# MSS_CTRL_MSS_CTRL_50D00000h register map
Vendor: Texas Instruments
Registers are 32-bit, read-write, reset values left out (the file's numbers can be read two ways) unless marked. A register's access mark holds for its fields unless they carry their own. Offsets are as the file gives them; [hi:lo] are bit positions; {n}, {i} and the like mark numbered series.

## MSS_CTRL (part 4 of 6)
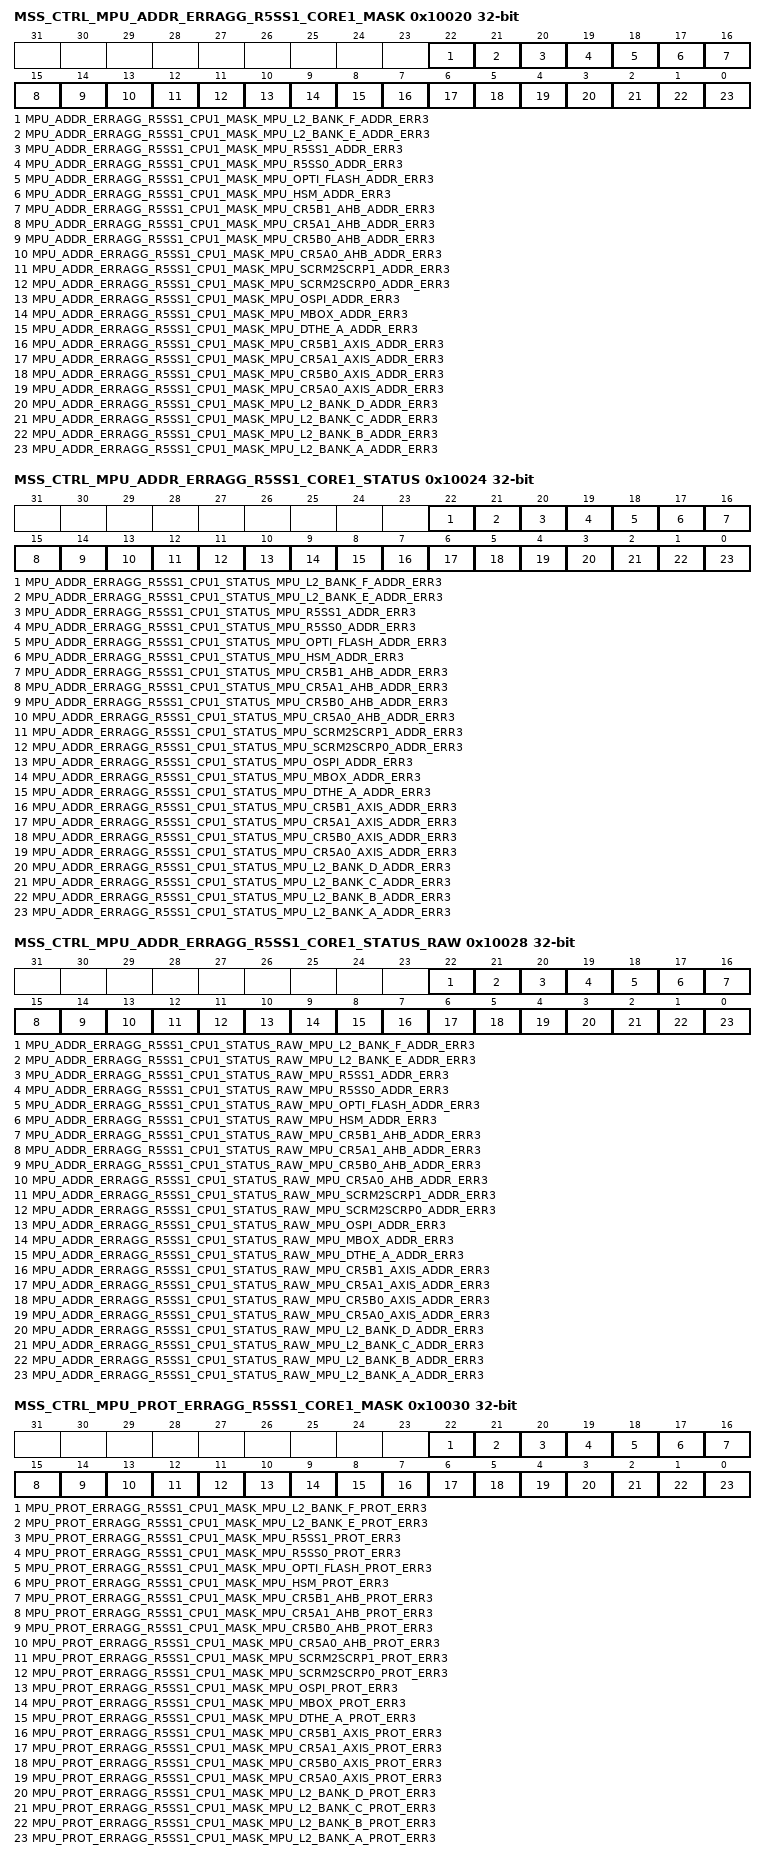
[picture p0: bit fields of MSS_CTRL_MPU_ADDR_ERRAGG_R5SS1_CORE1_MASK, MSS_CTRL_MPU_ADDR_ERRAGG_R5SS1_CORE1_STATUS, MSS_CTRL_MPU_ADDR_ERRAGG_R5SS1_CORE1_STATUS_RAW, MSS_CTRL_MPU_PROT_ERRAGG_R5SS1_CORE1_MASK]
0x10020 MSS_CTRL_MPU_ADDR_ERRAGG_R5SS1_CORE1_MASK
  [22] MPU_ADDR_ERRAGG_R5SS1_CPU1_MASK_MPU_L2_BANK_F_ADDR_ERR3 — Mask Error from MPU_ADDR_INTR to aggregated Error MPU_ADDR_INTR_ERRAGG1'b1 : Error is Masked1'b0 : Error is Unmasked
  [21] MPU_ADDR_ERRAGG_R5SS1_CPU1_MASK_MPU_L2_BANK_E_ADDR_ERR3 — Mask Error from MPU_ADDR_INTR to aggregated Error MPU_ADDR_INTR_ERRAGG1'b1 : Error is Masked1'b0 : Error is Unmasked
  [20] MPU_ADDR_ERRAGG_R5SS1_CPU1_MASK_MPU_R5SS1_ADDR_ERR3 — Mask Error from MPU_ADDR_INTR to aggregated Error MPU_ADDR_INTR_ERRAGG1'b1 : Error is Masked1'b0 : Error is Unmasked
  [19] MPU_ADDR_ERRAGG_R5SS1_CPU1_MASK_MPU_R5SS0_ADDR_ERR3 — Mask Error from MPU_ADDR_INTR to aggregated Error MPU_ADDR_INTR_ERRAGG1'b1 : Error is Masked1'b0 : Error is Unmasked
  [18] MPU_ADDR_ERRAGG_R5SS1_CPU1_MASK_MPU_OPTI_FLASH_ADDR_ERR3 — Mask Error from MPU_ADDR_INTR to aggregated Error MPU_ADDR_INTR_ERRAGG1'b1 : Error is Masked1'b0 : Error is Unmasked
  [17] MPU_ADDR_ERRAGG_R5SS1_CPU1_MASK_MPU_HSM_ADDR_ERR3 — Mask Error from MPU_ADDR_INTR to aggregated Error MPU_ADDR_INTR_ERRAGG1'b1 : Error is Masked1'b0 : Error is Unmasked
  [16] MPU_ADDR_ERRAGG_R5SS1_CPU1_MASK_MPU_CR5B1_AHB_ADDR_ERR3 — Mask Error from MPU_ADDR_INTR to aggregated Error MPU_ADDR_INTR_ERRAGG1'b1 : Error is Masked1'b0 : Error is Unmasked
  [15] MPU_ADDR_ERRAGG_R5SS1_CPU1_MASK_MPU_CR5A1_AHB_ADDR_ERR3 — Mask Error from MPU_ADDR_INTR to aggregated Error MPU_ADDR_INTR_ERRAGG1'b1 : Error is Masked1'b0 : Error is Unmasked
  [14] MPU_ADDR_ERRAGG_R5SS1_CPU1_MASK_MPU_CR5B0_AHB_ADDR_ERR3 — Mask Error from MPU_ADDR_INTR to aggregated Error MPU_ADDR_INTR_ERRAGG1'b1 : Error is Masked1'b0 : Error is Unmasked
  [13] MPU_ADDR_ERRAGG_R5SS1_CPU1_MASK_MPU_CR5A0_AHB_ADDR_ERR3 — Mask Error from MPU_ADDR_INTR to aggregated Error MPU_ADDR_INTR_ERRAGG1'b1 : Error is Masked1'b0 : Error is Unmasked
  [12] MPU_ADDR_ERRAGG_R5SS1_CPU1_MASK_MPU_SCRM2SCRP1_ADDR_ERR3 — Mask Error from MPU_ADDR_INTR to aggregated Error MPU_ADDR_INTR_ERRAGG1'b1 : Error is Masked1'b0 : Error is Unmasked
  [11] MPU_ADDR_ERRAGG_R5SS1_CPU1_MASK_MPU_SCRM2SCRP0_ADDR_ERR3 — Mask Error from MPU_ADDR_INTR to aggregated Error MPU_ADDR_INTR_ERRAGG1'b1 : Error is Masked1'b0 : Error is Unmasked
  [10] MPU_ADDR_ERRAGG_R5SS1_CPU1_MASK_MPU_OSPI_ADDR_ERR3 — Mask Error from MPU_ADDR_INTR to aggregated Error MPU_ADDR_INTR_ERRAGG1'b1 : Error is Masked1'b0 : Error is Unmasked
  [9] MPU_ADDR_ERRAGG_R5SS1_CPU1_MASK_MPU_MBOX_ADDR_ERR3 — Mask Error from MPU_ADDR_INTR to aggregated Error MPU_ADDR_INTR_ERRAGG1'b1 : Error is Masked1'b0 : Error is Unmasked
  [8] MPU_ADDR_ERRAGG_R5SS1_CPU1_MASK_MPU_DTHE_A_ADDR_ERR3 — Mask Error from MPU_ADDR_INTR to aggregated Error MPU_ADDR_INTR_ERRAGG1'b1 : Error is Masked1'b0 : Error is Unmasked
  [7] MPU_ADDR_ERRAGG_R5SS1_CPU1_MASK_MPU_CR5B1_AXIS_ADDR_ERR3 — Mask Error from MPU_ADDR_INTR to aggregated Error MPU_ADDR_INTR_ERRAGG1'b1 : Error is Masked1'b0 : Error is Unmasked
  [6] MPU_ADDR_ERRAGG_R5SS1_CPU1_MASK_MPU_CR5A1_AXIS_ADDR_ERR3 — Mask Error from MPU_ADDR_INTR to aggregated Error MPU_ADDR_INTR_ERRAGG1'b1 : Error is Masked1'b0 : Error is Unmasked
  [5] MPU_ADDR_ERRAGG_R5SS1_CPU1_MASK_MPU_CR5B0_AXIS_ADDR_ERR3 — Mask Error from MPU_ADDR_INTR to aggregated Error MPU_ADDR_INTR_ERRAGG1'b1 : Error is Masked1'b0 : Error is Unmasked
  [4] MPU_ADDR_ERRAGG_R5SS1_CPU1_MASK_MPU_CR5A0_AXIS_ADDR_ERR3 — Mask Error from MPU_ADDR_INTR to aggregated Error MPU_ADDR_INTR_ERRAGG1'b1 : Error is Masked1'b0 : Error is Unmasked
  [3] MPU_ADDR_ERRAGG_R5SS1_CPU1_MASK_MPU_L2_BANK_D_ADDR_ERR3 — Mask Error from MPU_ADDR_INTR to aggregated Error MPU_ADDR_INTR_ERRAGG1'b1 : Error is Masked1'b0 : Error is Unmasked
  [2] MPU_ADDR_ERRAGG_R5SS1_CPU1_MASK_MPU_L2_BANK_C_ADDR_ERR3 — Mask Error from MPU_ADDR_INTR to aggregated Error MPU_ADDR_INTR_ERRAGG1'b1 : Error is Masked1'b0 : Error is Unmasked
  [1] MPU_ADDR_ERRAGG_R5SS1_CPU1_MASK_MPU_L2_BANK_B_ADDR_ERR3 — Mask Error from MPU_ADDR_INTR to aggregated Error MPU_ADDR_INTR_ERRAGG1'b1 : Error is Masked1'b0 : Error is Unmasked
  [0] MPU_ADDR_ERRAGG_R5SS1_CPU1_MASK_MPU_L2_BANK_A_ADDR_ERR3 — Mask Error from MPU_ADDR_INTR to aggregated Error MPU_ADDR_INTR_ERRAGG1'b1 : Error is Masked1'b0 : Error is Unmasked
0x10024 MSS_CTRL_MPU_ADDR_ERRAGG_R5SS1_CORE1_STATUS
  [22] MPU_ADDR_ERRAGG_R5SS1_CPU1_STATUS_MPU_L2_BANK_F_ADDR_ERR3 — Status of Error from MPU_ADDR_INTR. Set only if Interupt is unmasked in MPU_ADDR_INTR_ERRAGG_MASKWrie 0x1 to clear this Error.
  [21] MPU_ADDR_ERRAGG_R5SS1_CPU1_STATUS_MPU_L2_BANK_E_ADDR_ERR3 — Status of Error from MPU_ADDR_INTR. Set only if Interupt is unmasked in MPU_ADDR_INTR_ERRAGG_MASKWrie 0x1 to clear this Error.
  [20] MPU_ADDR_ERRAGG_R5SS1_CPU1_STATUS_MPU_R5SS1_ADDR_ERR3 — Status of Error from MPU_ADDR_INTR. Set only if Interupt is unmasked in MPU_ADDR_INTR_ERRAGG_MASKWrie 0x1 to clear this Error.
  [19] MPU_ADDR_ERRAGG_R5SS1_CPU1_STATUS_MPU_R5SS0_ADDR_ERR3 — Status of Error from MPU_ADDR_INTR. Set only if Interupt is unmasked in MPU_ADDR_INTR_ERRAGG_MASKWrie 0x1 to clear this Error.
  [18] MPU_ADDR_ERRAGG_R5SS1_CPU1_STATUS_MPU_OPTI_FLASH_ADDR_ERR3 — Status of Error from MPU_ADDR_INTR. Set only if Interupt is unmasked in MPU_ADDR_INTR_ERRAGG_MASKWrie 0x1 to clear this Error.
  [17] MPU_ADDR_ERRAGG_R5SS1_CPU1_STATUS_MPU_HSM_ADDR_ERR3 — Status of Error from MPU_ADDR_INTR. Set only if Interupt is unmasked in MPU_ADDR_INTR_ERRAGG_MASKWrie 0x1 to clear this Error.
  [16] MPU_ADDR_ERRAGG_R5SS1_CPU1_STATUS_MPU_CR5B1_AHB_ADDR_ERR3 — Status of Error from MPU_ADDR_INTR. Set only if Interupt is unmasked in MPU_ADDR_INTR_ERRAGG_MASKWrie 0x1 to clear this Error.
  [15] MPU_ADDR_ERRAGG_R5SS1_CPU1_STATUS_MPU_CR5A1_AHB_ADDR_ERR3 — Status of Error from MPU_ADDR_INTR. Set only if Interupt is unmasked in MPU_ADDR_INTR_ERRAGG_MASKWrie 0x1 to clear this Error.
  [14] MPU_ADDR_ERRAGG_R5SS1_CPU1_STATUS_MPU_CR5B0_AHB_ADDR_ERR3 — Status of Error from MPU_ADDR_INTR. Set only if Interupt is unmasked in MPU_ADDR_INTR_ERRAGG_MASKWrie 0x1 to clear this Error.
  [13] MPU_ADDR_ERRAGG_R5SS1_CPU1_STATUS_MPU_CR5A0_AHB_ADDR_ERR3 — Status of Error from MPU_ADDR_INTR. Set only if Interupt is unmasked in MPU_ADDR_INTR_ERRAGG_MASKWrie 0x1 to clear this Error.
  [12] MPU_ADDR_ERRAGG_R5SS1_CPU1_STATUS_MPU_SCRM2SCRP1_ADDR_ERR3 — Status of Error from MPU_ADDR_INTR. Set only if Interupt is unmasked in MPU_ADDR_INTR_ERRAGG_MASKWrie 0x1 to clear this Error.
  [11] MPU_ADDR_ERRAGG_R5SS1_CPU1_STATUS_MPU_SCRM2SCRP0_ADDR_ERR3 — Status of Error from MPU_ADDR_INTR. Set only if Interupt is unmasked in MPU_ADDR_INTR_ERRAGG_MASKWrie 0x1 to clear this Error.
  [10] MPU_ADDR_ERRAGG_R5SS1_CPU1_STATUS_MPU_OSPI_ADDR_ERR3 — Status of Error from MPU_ADDR_INTR. Set only if Interupt is unmasked in MPU_ADDR_INTR_ERRAGG_MASKWrie 0x1 to clear this Error.
  [9] MPU_ADDR_ERRAGG_R5SS1_CPU1_STATUS_MPU_MBOX_ADDR_ERR3 — Status of Error from MPU_ADDR_INTR. Set only if Interupt is unmasked in MPU_ADDR_INTR_ERRAGG_MASKWrie 0x1 to clear this Error.
  [8] MPU_ADDR_ERRAGG_R5SS1_CPU1_STATUS_MPU_DTHE_A_ADDR_ERR3 — Status of Error from MPU_ADDR_INTR. Set only if Interupt is unmasked in MPU_ADDR_INTR_ERRAGG_MASKWrie 0x1 to clear this Error.
  [7] MPU_ADDR_ERRAGG_R5SS1_CPU1_STATUS_MPU_CR5B1_AXIS_ADDR_ERR3 — Status of Error from MPU_ADDR_INTR. Set only if Interupt is unmasked in MPU_ADDR_INTR_ERRAGG_MASKWrie 0x1 to clear this Error.
  [6] MPU_ADDR_ERRAGG_R5SS1_CPU1_STATUS_MPU_CR5A1_AXIS_ADDR_ERR3 — Status of Error from MPU_ADDR_INTR. Set only if Interupt is unmasked in MPU_ADDR_INTR_ERRAGG_MASKWrie 0x1 to clear this Error.
  [5] MPU_ADDR_ERRAGG_R5SS1_CPU1_STATUS_MPU_CR5B0_AXIS_ADDR_ERR3 — Status of Error from MPU_ADDR_INTR. Set only if Interupt is unmasked in MPU_ADDR_INTR_ERRAGG_MASKWrie 0x1 to clear this Error.
  [4] MPU_ADDR_ERRAGG_R5SS1_CPU1_STATUS_MPU_CR5A0_AXIS_ADDR_ERR3 — Status of Error from MPU_ADDR_INTR. Set only if Interupt is unmasked in MPU_ADDR_INTR_ERRAGG_MASKWrie 0x1 to clear this Error.
  [3] MPU_ADDR_ERRAGG_R5SS1_CPU1_STATUS_MPU_L2_BANK_D_ADDR_ERR3 — Status of Error from MPU_ADDR_INTR. Set only if Interupt is unmasked in MPU_ADDR_INTR_ERRAGG_MASKWrie 0x1 to clear this Error.
  [2] MPU_ADDR_ERRAGG_R5SS1_CPU1_STATUS_MPU_L2_BANK_C_ADDR_ERR3 — Status of Error from MPU_ADDR_INTR. Set only if Interupt is unmasked in MPU_ADDR_INTR_ERRAGG_MASKWrie 0x1 to clear this Error.
  [1] MPU_ADDR_ERRAGG_R5SS1_CPU1_STATUS_MPU_L2_BANK_B_ADDR_ERR3 — Status of Error from MPU_ADDR_INTR. Set only if Interupt is unmasked in MPU_ADDR_INTR_ERRAGG_MASKWrie 0x1 to clear this Error.
  [0] MPU_ADDR_ERRAGG_R5SS1_CPU1_STATUS_MPU_L2_BANK_A_ADDR_ERR3 — Status of Error from MPU_ADDR_INTR. Set only if Interupt is unmasked in MPU_ADDR_INTR_ERRAGG_MASKWrie 0x1 to clear this Error.
0x10028 MSS_CTRL_MPU_ADDR_ERRAGG_R5SS1_CORE1_STATUS_RAW
  [22] MPU_ADDR_ERRAGG_R5SS1_CPU1_STATUS_RAW_MPU_L2_BANK_F_ADDR_ERR3 — Raw Status of Error from MPU_ADDR_INTR. Set irrespective if the Interupt is masked or unmasked in MPU_ADDR_INTR_ERRAGG_MASK
  [21] MPU_ADDR_ERRAGG_R5SS1_CPU1_STATUS_RAW_MPU_L2_BANK_E_ADDR_ERR3 — Raw Status of Error from MPU_ADDR_INTR. Set irrespective if the Interupt is masked or unmasked in MPU_ADDR_INTR_ERRAGG_MASK
  [20] MPU_ADDR_ERRAGG_R5SS1_CPU1_STATUS_RAW_MPU_R5SS1_ADDR_ERR3 — Raw Status of Error from MPU_ADDR_INTR. Set irrespective if the Interupt is masked or unmasked in MPU_ADDR_INTR_ERRAGG_MASK
  [19] MPU_ADDR_ERRAGG_R5SS1_CPU1_STATUS_RAW_MPU_R5SS0_ADDR_ERR3 — Raw Status of Error from MPU_ADDR_INTR. Set irrespective if the Interupt is masked or unmasked in MPU_ADDR_INTR_ERRAGG_MASK
  [18] MPU_ADDR_ERRAGG_R5SS1_CPU1_STATUS_RAW_MPU_OPTI_FLASH_ADDR_ERR3 — Raw Status of Error from MPU_ADDR_INTR. Set irrespective if the Interupt is masked or unmasked in MPU_ADDR_INTR_ERRAGG_MASK
  [17] MPU_ADDR_ERRAGG_R5SS1_CPU1_STATUS_RAW_MPU_HSM_ADDR_ERR3 — Raw Status of Error from MPU_ADDR_INTR. Set irrespective if the Interupt is masked or unmasked in MPU_ADDR_INTR_ERRAGG_MASK
  [16] MPU_ADDR_ERRAGG_R5SS1_CPU1_STATUS_RAW_MPU_CR5B1_AHB_ADDR_ERR3 — Raw Status of Error from MPU_ADDR_INTR. Set irrespective if the Interupt is masked or unmasked in MPU_ADDR_INTR_ERRAGG_MASK
  [15] MPU_ADDR_ERRAGG_R5SS1_CPU1_STATUS_RAW_MPU_CR5A1_AHB_ADDR_ERR3 — Raw Status of Error from MPU_ADDR_INTR. Set irrespective if the Interupt is masked or unmasked in MPU_ADDR_INTR_ERRAGG_MASK
  [14] MPU_ADDR_ERRAGG_R5SS1_CPU1_STATUS_RAW_MPU_CR5B0_AHB_ADDR_ERR3 — Raw Status of Error from MPU_ADDR_INTR. Set irrespective if the Interupt is masked or unmasked in MPU_ADDR_INTR_ERRAGG_MASK
  [13] MPU_ADDR_ERRAGG_R5SS1_CPU1_STATUS_RAW_MPU_CR5A0_AHB_ADDR_ERR3 — Raw Status of Error from MPU_ADDR_INTR. Set irrespective if the Interupt is masked or unmasked in MPU_ADDR_INTR_ERRAGG_MASK
  [12] MPU_ADDR_ERRAGG_R5SS1_CPU1_STATUS_RAW_MPU_SCRM2SCRP1_ADDR_ERR3 — Raw Status of Error from MPU_ADDR_INTR. Set irrespective if the Interupt is masked or unmasked in MPU_ADDR_INTR_ERRAGG_MASK
  [11] MPU_ADDR_ERRAGG_R5SS1_CPU1_STATUS_RAW_MPU_SCRM2SCRP0_ADDR_ERR3 — Raw Status of Error from MPU_ADDR_INTR. Set irrespective if the Interupt is masked or unmasked in MPU_ADDR_INTR_ERRAGG_MASK
  [10] MPU_ADDR_ERRAGG_R5SS1_CPU1_STATUS_RAW_MPU_OSPI_ADDR_ERR3 — Raw Status of Error from MPU_ADDR_INTR. Set irrespective if the Interupt is masked or unmasked in MPU_ADDR_INTR_ERRAGG_MASK
  [9] MPU_ADDR_ERRAGG_R5SS1_CPU1_STATUS_RAW_MPU_MBOX_ADDR_ERR3 — Raw Status of Error from MPU_ADDR_INTR. Set irrespective if the Interupt is masked or unmasked in MPU_ADDR_INTR_ERRAGG_MASK
  [8] MPU_ADDR_ERRAGG_R5SS1_CPU1_STATUS_RAW_MPU_DTHE_A_ADDR_ERR3 — Raw Status of Error from MPU_ADDR_INTR. Set irrespective if the Interupt is masked or unmasked in MPU_ADDR_INTR_ERRAGG_MASK
  [7] MPU_ADDR_ERRAGG_R5SS1_CPU1_STATUS_RAW_MPU_CR5B1_AXIS_ADDR_ERR3 — Raw Status of Error from MPU_ADDR_INTR. Set irrespective if the Interupt is masked or unmasked in MPU_ADDR_INTR_ERRAGG_MASK
  [6] MPU_ADDR_ERRAGG_R5SS1_CPU1_STATUS_RAW_MPU_CR5A1_AXIS_ADDR_ERR3 — Raw Status of Error from MPU_ADDR_INTR. Set irrespective if the Interupt is masked or unmasked in MPU_ADDR_INTR_ERRAGG_MASK
  [5] MPU_ADDR_ERRAGG_R5SS1_CPU1_STATUS_RAW_MPU_CR5B0_AXIS_ADDR_ERR3 — Raw Status of Error from MPU_ADDR_INTR. Set irrespective if the Interupt is masked or unmasked in MPU_ADDR_INTR_ERRAGG_MASK
  [4] MPU_ADDR_ERRAGG_R5SS1_CPU1_STATUS_RAW_MPU_CR5A0_AXIS_ADDR_ERR3 — Raw Status of Error from MPU_ADDR_INTR. Set irrespective if the Interupt is masked or unmasked in MPU_ADDR_INTR_ERRAGG_MASK
  [3] MPU_ADDR_ERRAGG_R5SS1_CPU1_STATUS_RAW_MPU_L2_BANK_D_ADDR_ERR3 — Raw Status of Error from MPU_ADDR_INTR. Set irrespective if the Interupt is masked or unmasked in MPU_ADDR_INTR_ERRAGG_MASK
  [2] MPU_ADDR_ERRAGG_R5SS1_CPU1_STATUS_RAW_MPU_L2_BANK_C_ADDR_ERR3 — Raw Status of Error from MPU_ADDR_INTR. Set irrespective if the Interupt is masked or unmasked in MPU_ADDR_INTR_ERRAGG_MASK
  [1] MPU_ADDR_ERRAGG_R5SS1_CPU1_STATUS_RAW_MPU_L2_BANK_B_ADDR_ERR3 — Raw Status of Error from MPU_ADDR_INTR. Set irrespective if the Interupt is masked or unmasked in MPU_ADDR_INTR_ERRAGG_MASK
  [0] MPU_ADDR_ERRAGG_R5SS1_CPU1_STATUS_RAW_MPU_L2_BANK_A_ADDR_ERR3 — Raw Status of Error from MPU_ADDR_INTR. Set irrespective if the Interupt is masked or unmasked in MPU_ADDR_INTR_ERRAGG_MASK
0x10030 MSS_CTRL_MPU_PROT_ERRAGG_R5SS1_CORE1_MASK
  [22] MPU_PROT_ERRAGG_R5SS1_CPU1_MASK_MPU_L2_BANK_F_PROT_ERR3 — Mask Error from MPU_PROT_INTR to aggregated Error MPU_PROT_INTR_ERRAGG1'b1 : Error is Masked1'b0 : Error is Unmasked
  [21] MPU_PROT_ERRAGG_R5SS1_CPU1_MASK_MPU_L2_BANK_E_PROT_ERR3 — Mask Error from MPU_PROT_INTR to aggregated Error MPU_PROT_INTR_ERRAGG1'b1 : Error is Masked1'b0 : Error is Unmasked
  [20] MPU_PROT_ERRAGG_R5SS1_CPU1_MASK_MPU_R5SS1_PROT_ERR3 — Mask Error from MPU_PROT_INTR to aggregated Error MPU_PROT_INTR_ERRAGG1'b1 : Error is Masked1'b0 : Error is Unmasked
  [19] MPU_PROT_ERRAGG_R5SS1_CPU1_MASK_MPU_R5SS0_PROT_ERR3 — Mask Error from MPU_PROT_INTR to aggregated Error MPU_PROT_INTR_ERRAGG1'b1 : Error is Masked1'b0 : Error is Unmasked
  [18] MPU_PROT_ERRAGG_R5SS1_CPU1_MASK_MPU_OPTI_FLASH_PROT_ERR3 — Mask Error from MPU_PROT_INTR to aggregated Error MPU_PROT_INTR_ERRAGG1'b1 : Error is Masked1'b0 : Error is Unmasked
  [17] MPU_PROT_ERRAGG_R5SS1_CPU1_MASK_MPU_HSM_PROT_ERR3 — Mask Error from MPU_PROT_INTR to aggregated Error MPU_PROT_INTR_ERRAGG1'b1 : Error is Masked1'b0 : Error is Unmasked
  [16] MPU_PROT_ERRAGG_R5SS1_CPU1_MASK_MPU_CR5B1_AHB_PROT_ERR3 — Mask Error from MPU_PROT_INTR to aggregated Error MPU_PROT_INTR_ERRAGG1'b1 : Error is Masked1'b0 : Error is Unmasked
  [15] MPU_PROT_ERRAGG_R5SS1_CPU1_MASK_MPU_CR5A1_AHB_PROT_ERR3 — Mask Error from MPU_PROT_INTR to aggregated Error MPU_PROT_INTR_ERRAGG1'b1 : Error is Masked1'b0 : Error is Unmasked
  [14] MPU_PROT_ERRAGG_R5SS1_CPU1_MASK_MPU_CR5B0_AHB_PROT_ERR3 — Mask Error from MPU_PROT_INTR to aggregated Error MPU_PROT_INTR_ERRAGG1'b1 : Error is Masked1'b0 : Error is Unmasked
  [13] MPU_PROT_ERRAGG_R5SS1_CPU1_MASK_MPU_CR5A0_AHB_PROT_ERR3 — Mask Error from MPU_PROT_INTR to aggregated Error MPU_PROT_INTR_ERRAGG1'b1 : Error is Masked1'b0 : Error is Unmasked
  [12] MPU_PROT_ERRAGG_R5SS1_CPU1_MASK_MPU_SCRM2SCRP1_PROT_ERR3 — Mask Error from MPU_PROT_INTR to aggregated Error MPU_PROT_INTR_ERRAGG1'b1 : Error is Masked1'b0 : Error is Unmasked
  [11] MPU_PROT_ERRAGG_R5SS1_CPU1_MASK_MPU_SCRM2SCRP0_PROT_ERR3 — Mask Error from MPU_PROT_INTR to aggregated Error MPU_PROT_INTR_ERRAGG1'b1 : Error is Masked1'b0 : Error is Unmasked
  [10] MPU_PROT_ERRAGG_R5SS1_CPU1_MASK_MPU_OSPI_PROT_ERR3 — Mask Error from MPU_PROT_INTR to aggregated Error MPU_PROT_INTR_ERRAGG1'b1 : Error is Masked1'b0 : Error is Unmasked
  [9] MPU_PROT_ERRAGG_R5SS1_CPU1_MASK_MPU_MBOX_PROT_ERR3 — Mask Error from MPU_PROT_INTR to aggregated Error MPU_PROT_INTR_ERRAGG1'b1 : Error is Masked1'b0 : Error is Unmasked
  [8] MPU_PROT_ERRAGG_R5SS1_CPU1_MASK_MPU_DTHE_A_PROT_ERR3 — Mask Error from MPU_PROT_INTR to aggregated Error MPU_PROT_INTR_ERRAGG1'b1 : Error is Masked1'b0 : Error is Unmasked
  [7] MPU_PROT_ERRAGG_R5SS1_CPU1_MASK_MPU_CR5B1_AXIS_PROT_ERR3 — Mask Error from MPU_PROT_INTR to aggregated Error MPU_PROT_INTR_ERRAGG1'b1 : Error is Masked1'b0 : Error is Unmasked
  [6] MPU_PROT_ERRAGG_R5SS1_CPU1_MASK_MPU_CR5A1_AXIS_PROT_ERR3 — Mask Error from MPU_PROT_INTR to aggregated Error MPU_PROT_INTR_ERRAGG1'b1 : Error is Masked1'b0 : Error is Unmasked
  [5] MPU_PROT_ERRAGG_R5SS1_CPU1_MASK_MPU_CR5B0_AXIS_PROT_ERR3 — Mask Error from MPU_PROT_INTR to aggregated Error MPU_PROT_INTR_ERRAGG1'b1 : Error is Masked1'b0 : Error is Unmasked
  [4] MPU_PROT_ERRAGG_R5SS1_CPU1_MASK_MPU_CR5A0_AXIS_PROT_ERR3 — Mask Error from MPU_PROT_INTR to aggregated Error MPU_PROT_INTR_ERRAGG1'b1 : Error is Masked1'b0 : Error is Unmasked
  [3] MPU_PROT_ERRAGG_R5SS1_CPU1_MASK_MPU_L2_BANK_D_PROT_ERR3 — Mask Error from MPU_PROT_INTR to aggregated Error MPU_PROT_INTR_ERRAGG1'b1 : Error is Masked1'b0 : Error is Unmasked
  [2] MPU_PROT_ERRAGG_R5SS1_CPU1_MASK_MPU_L2_BANK_C_PROT_ERR3 — Mask Error from MPU_PROT_INTR to aggregated Error MPU_PROT_INTR_ERRAGG1'b1 : Error is Masked1'b0 : Error is Unmasked
  [1] MPU_PROT_ERRAGG_R5SS1_CPU1_MASK_MPU_L2_BANK_B_PROT_ERR3 — Mask Error from MPU_PROT_INTR to aggregated Error MPU_PROT_INTR_ERRAGG1'b1 : Error is Masked1'b0 : Error is Unmasked
  [0] MPU_PROT_ERRAGG_R5SS1_CPU1_MASK_MPU_L2_BANK_A_PROT_ERR3 — Mask Error from MPU_PROT_INTR to aggregated Error MPU_PROT_INTR_ERRAGG1'b1 : Error is Masked1'b0 : Error is Unmasked
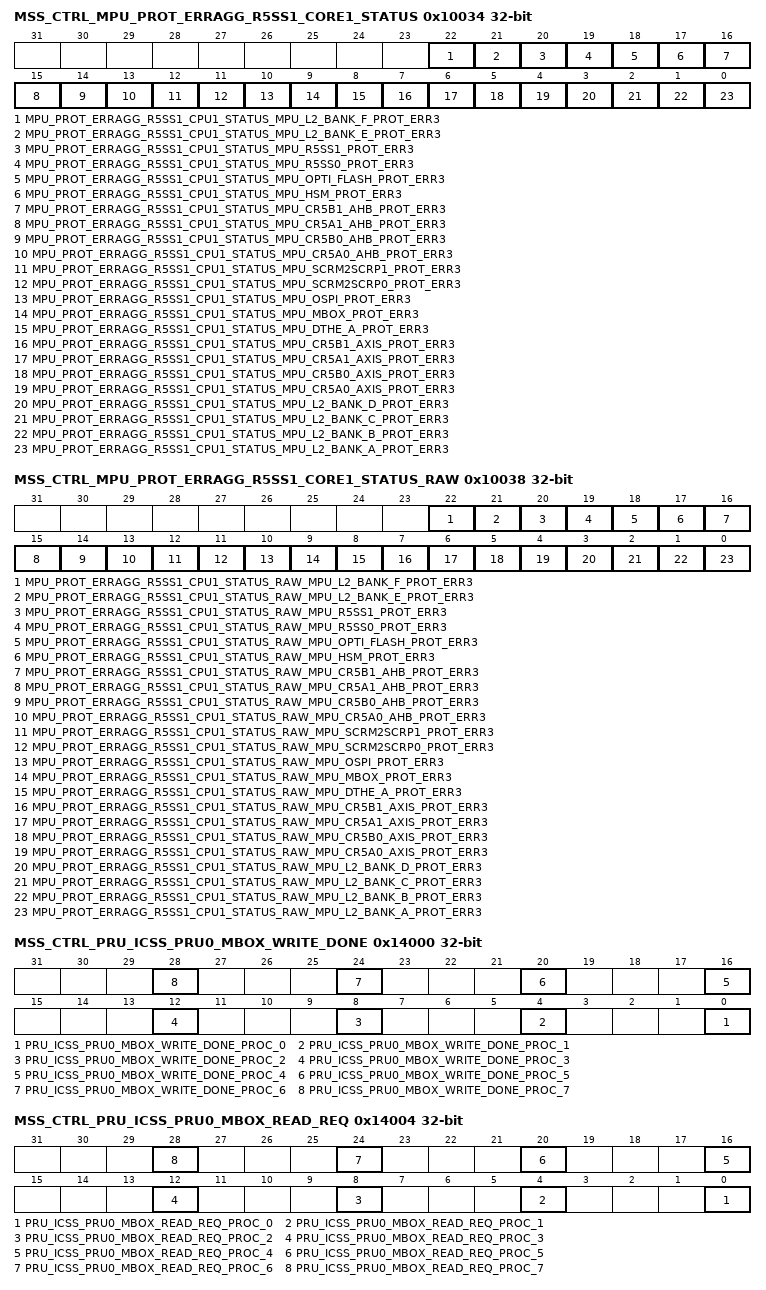
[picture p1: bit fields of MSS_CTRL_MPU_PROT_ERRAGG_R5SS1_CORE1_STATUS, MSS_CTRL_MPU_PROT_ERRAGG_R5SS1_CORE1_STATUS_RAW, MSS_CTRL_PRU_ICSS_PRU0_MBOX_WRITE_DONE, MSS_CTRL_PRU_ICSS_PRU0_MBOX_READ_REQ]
0x10034 MSS_CTRL_MPU_PROT_ERRAGG_R5SS1_CORE1_STATUS
  [22] MPU_PROT_ERRAGG_R5SS1_CPU1_STATUS_MPU_L2_BANK_F_PROT_ERR3 — Status of Error from MPU_PROT_INTR. Set only if Interupt is unmasked in MPU_PROT_INTR_ERRAGG_MASKWrie 0x1 to clear this Error.
  [21] MPU_PROT_ERRAGG_R5SS1_CPU1_STATUS_MPU_L2_BANK_E_PROT_ERR3 — Status of Error from MPU_PROT_INTR. Set only if Interupt is unmasked in MPU_PROT_INTR_ERRAGG_MASKWrie 0x1 to clear this Error.
  [20] MPU_PROT_ERRAGG_R5SS1_CPU1_STATUS_MPU_R5SS1_PROT_ERR3 — Status of Error from MPU_PROT_INTR. Set only if Interupt is unmasked in MPU_PROT_INTR_ERRAGG_MASKWrie 0x1 to clear this Error.
  [19] MPU_PROT_ERRAGG_R5SS1_CPU1_STATUS_MPU_R5SS0_PROT_ERR3 — Status of Error from MPU_PROT_INTR. Set only if Interupt is unmasked in MPU_PROT_INTR_ERRAGG_MASKWrie 0x1 to clear this Error.
  [18] MPU_PROT_ERRAGG_R5SS1_CPU1_STATUS_MPU_OPTI_FLASH_PROT_ERR3 — Status of Error from MPU_PROT_INTR. Set only if Interupt is unmasked in MPU_PROT_INTR_ERRAGG_MASKWrie 0x1 to clear this Error.
  [17] MPU_PROT_ERRAGG_R5SS1_CPU1_STATUS_MPU_HSM_PROT_ERR3 — Status of Error from MPU_PROT_INTR. Set only if Interupt is unmasked in MPU_PROT_INTR_ERRAGG_MASKWrie 0x1 to clear this Error.
  [16] MPU_PROT_ERRAGG_R5SS1_CPU1_STATUS_MPU_CR5B1_AHB_PROT_ERR3 — Status of Error from MPU_PROT_INTR. Set only if Interupt is unmasked in MPU_PROT_INTR_ERRAGG_MASKWrie 0x1 to clear this Error.
  [15] MPU_PROT_ERRAGG_R5SS1_CPU1_STATUS_MPU_CR5A1_AHB_PROT_ERR3 — Status of Error from MPU_PROT_INTR. Set only if Interupt is unmasked in MPU_PROT_INTR_ERRAGG_MASKWrie 0x1 to clear this Error.
  [14] MPU_PROT_ERRAGG_R5SS1_CPU1_STATUS_MPU_CR5B0_AHB_PROT_ERR3 — Status of Error from MPU_PROT_INTR. Set only if Interupt is unmasked in MPU_PROT_INTR_ERRAGG_MASKWrie 0x1 to clear this Error.
  [13] MPU_PROT_ERRAGG_R5SS1_CPU1_STATUS_MPU_CR5A0_AHB_PROT_ERR3 — Status of Error from MPU_PROT_INTR. Set only if Interupt is unmasked in MPU_PROT_INTR_ERRAGG_MASKWrie 0x1 to clear this Error.
  [12] MPU_PROT_ERRAGG_R5SS1_CPU1_STATUS_MPU_SCRM2SCRP1_PROT_ERR3 — Status of Error from MPU_PROT_INTR. Set only if Interupt is unmasked in MPU_PROT_INTR_ERRAGG_MASKWrie 0x1 to clear this Error.
  [11] MPU_PROT_ERRAGG_R5SS1_CPU1_STATUS_MPU_SCRM2SCRP0_PROT_ERR3 — Status of Error from MPU_PROT_INTR. Set only if Interupt is unmasked in MPU_PROT_INTR_ERRAGG_MASKWrie 0x1 to clear this Error.
  [10] MPU_PROT_ERRAGG_R5SS1_CPU1_STATUS_MPU_OSPI_PROT_ERR3 — Status of Error from MPU_PROT_INTR. Set only if Interupt is unmasked in MPU_PROT_INTR_ERRAGG_MASKWrie 0x1 to clear this Error.
  [9] MPU_PROT_ERRAGG_R5SS1_CPU1_STATUS_MPU_MBOX_PROT_ERR3 — Status of Error from MPU_PROT_INTR. Set only if Interupt is unmasked in MPU_PROT_INTR_ERRAGG_MASKWrie 0x1 to clear this Error.
  [8] MPU_PROT_ERRAGG_R5SS1_CPU1_STATUS_MPU_DTHE_A_PROT_ERR3 — Status of Error from MPU_PROT_INTR. Set only if Interupt is unmasked in MPU_PROT_INTR_ERRAGG_MASKWrie 0x1 to clear this Error.
  [7] MPU_PROT_ERRAGG_R5SS1_CPU1_STATUS_MPU_CR5B1_AXIS_PROT_ERR3 — Status of Error from MPU_PROT_INTR. Set only if Interupt is unmasked in MPU_PROT_INTR_ERRAGG_MASKWrie 0x1 to clear this Error.
  [6] MPU_PROT_ERRAGG_R5SS1_CPU1_STATUS_MPU_CR5A1_AXIS_PROT_ERR3 — Status of Error from MPU_PROT_INTR. Set only if Interupt is unmasked in MPU_PROT_INTR_ERRAGG_MASKWrie 0x1 to clear this Error.
  [5] MPU_PROT_ERRAGG_R5SS1_CPU1_STATUS_MPU_CR5B0_AXIS_PROT_ERR3 — Status of Error from MPU_PROT_INTR. Set only if Interupt is unmasked in MPU_PROT_INTR_ERRAGG_MASKWrie 0x1 to clear this Error.
  [4] MPU_PROT_ERRAGG_R5SS1_CPU1_STATUS_MPU_CR5A0_AXIS_PROT_ERR3 — Status of Error from MPU_PROT_INTR. Set only if Interupt is unmasked in MPU_PROT_INTR_ERRAGG_MASKWrie 0x1 to clear this Error.
  [3] MPU_PROT_ERRAGG_R5SS1_CPU1_STATUS_MPU_L2_BANK_D_PROT_ERR3 — Status of Error from MPU_PROT_INTR. Set only if Interupt is unmasked in MPU_PROT_INTR_ERRAGG_MASKWrie 0x1 to clear this Error.
  [2] MPU_PROT_ERRAGG_R5SS1_CPU1_STATUS_MPU_L2_BANK_C_PROT_ERR3 — Status of Error from MPU_PROT_INTR. Set only if Interupt is unmasked in MPU_PROT_INTR_ERRAGG_MASKWrie 0x1 to clear this Error.
  [1] MPU_PROT_ERRAGG_R5SS1_CPU1_STATUS_MPU_L2_BANK_B_PROT_ERR3 — Status of Error from MPU_PROT_INTR. Set only if Interupt is unmasked in MPU_PROT_INTR_ERRAGG_MASKWrie 0x1 to clear this Error.
  [0] MPU_PROT_ERRAGG_R5SS1_CPU1_STATUS_MPU_L2_BANK_A_PROT_ERR3 — Status of Error from MPU_PROT_INTR. Set only if Interupt is unmasked in MPU_PROT_INTR_ERRAGG_MASKWrie 0x1 to clear this Error.
0x10038 MSS_CTRL_MPU_PROT_ERRAGG_R5SS1_CORE1_STATUS_RAW
  [22] MPU_PROT_ERRAGG_R5SS1_CPU1_STATUS_RAW_MPU_L2_BANK_F_PROT_ERR3 — Raw Status of Error from MPU_PROT_INTR. Set irrespective if the Interupt is masked or unmasked in MPU_PROT_INTR_ERRAGG_MASK
  [21] MPU_PROT_ERRAGG_R5SS1_CPU1_STATUS_RAW_MPU_L2_BANK_E_PROT_ERR3 — Raw Status of Error from MPU_PROT_INTR. Set irrespective if the Interupt is masked or unmasked in MPU_PROT_INTR_ERRAGG_MASK
  [20] MPU_PROT_ERRAGG_R5SS1_CPU1_STATUS_RAW_MPU_R5SS1_PROT_ERR3 — Raw Status of Error from MPU_PROT_INTR. Set irrespective if the Interupt is masked or unmasked in MPU_PROT_INTR_ERRAGG_MASK
  [19] MPU_PROT_ERRAGG_R5SS1_CPU1_STATUS_RAW_MPU_R5SS0_PROT_ERR3 — Raw Status of Error from MPU_PROT_INTR. Set irrespective if the Interupt is masked or unmasked in MPU_PROT_INTR_ERRAGG_MASK
  [18] MPU_PROT_ERRAGG_R5SS1_CPU1_STATUS_RAW_MPU_OPTI_FLASH_PROT_ERR3 — Raw Status of Error from MPU_PROT_INTR. Set irrespective if the Interupt is masked or unmasked in MPU_PROT_INTR_ERRAGG_MASK
  [17] MPU_PROT_ERRAGG_R5SS1_CPU1_STATUS_RAW_MPU_HSM_PROT_ERR3 — Raw Status of Error from MPU_PROT_INTR. Set irrespective if the Interupt is masked or unmasked in MPU_PROT_INTR_ERRAGG_MASK
  [16] MPU_PROT_ERRAGG_R5SS1_CPU1_STATUS_RAW_MPU_CR5B1_AHB_PROT_ERR3 — Raw Status of Error from MPU_PROT_INTR. Set irrespective if the Interupt is masked or unmasked in MPU_PROT_INTR_ERRAGG_MASK
  [15] MPU_PROT_ERRAGG_R5SS1_CPU1_STATUS_RAW_MPU_CR5A1_AHB_PROT_ERR3 — Raw Status of Error from MPU_PROT_INTR. Set irrespective if the Interupt is masked or unmasked in MPU_PROT_INTR_ERRAGG_MASK
  [14] MPU_PROT_ERRAGG_R5SS1_CPU1_STATUS_RAW_MPU_CR5B0_AHB_PROT_ERR3 — Raw Status of Error from MPU_PROT_INTR. Set irrespective if the Interupt is masked or unmasked in MPU_PROT_INTR_ERRAGG_MASK
  [13] MPU_PROT_ERRAGG_R5SS1_CPU1_STATUS_RAW_MPU_CR5A0_AHB_PROT_ERR3 — Raw Status of Error from MPU_PROT_INTR. Set irrespective if the Interupt is masked or unmasked in MPU_PROT_INTR_ERRAGG_MASK
  [12] MPU_PROT_ERRAGG_R5SS1_CPU1_STATUS_RAW_MPU_SCRM2SCRP1_PROT_ERR3 — Raw Status of Error from MPU_PROT_INTR. Set irrespective if the Interupt is masked or unmasked in MPU_PROT_INTR_ERRAGG_MASK
  [11] MPU_PROT_ERRAGG_R5SS1_CPU1_STATUS_RAW_MPU_SCRM2SCRP0_PROT_ERR3 — Raw Status of Error from MPU_PROT_INTR. Set irrespective if the Interupt is masked or unmasked in MPU_PROT_INTR_ERRAGG_MASK
  [10] MPU_PROT_ERRAGG_R5SS1_CPU1_STATUS_RAW_MPU_OSPI_PROT_ERR3 — Raw Status of Error from MPU_PROT_INTR. Set irrespective if the Interupt is masked or unmasked in MPU_PROT_INTR_ERRAGG_MASK
  [9] MPU_PROT_ERRAGG_R5SS1_CPU1_STATUS_RAW_MPU_MBOX_PROT_ERR3 — Raw Status of Error from MPU_PROT_INTR. Set irrespective if the Interupt is masked or unmasked in MPU_PROT_INTR_ERRAGG_MASK
  [8] MPU_PROT_ERRAGG_R5SS1_CPU1_STATUS_RAW_MPU_DTHE_A_PROT_ERR3 — Raw Status of Error from MPU_PROT_INTR. Set irrespective if the Interupt is masked or unmasked in MPU_PROT_INTR_ERRAGG_MASK
  [7] MPU_PROT_ERRAGG_R5SS1_CPU1_STATUS_RAW_MPU_CR5B1_AXIS_PROT_ERR3 — Raw Status of Error from MPU_PROT_INTR. Set irrespective if the Interupt is masked or unmasked in MPU_PROT_INTR_ERRAGG_MASK
  [6] MPU_PROT_ERRAGG_R5SS1_CPU1_STATUS_RAW_MPU_CR5A1_AXIS_PROT_ERR3 — Raw Status of Error from MPU_PROT_INTR. Set irrespective if the Interupt is masked or unmasked in MPU_PROT_INTR_ERRAGG_MASK
  [5] MPU_PROT_ERRAGG_R5SS1_CPU1_STATUS_RAW_MPU_CR5B0_AXIS_PROT_ERR3 — Raw Status of Error from MPU_PROT_INTR. Set irrespective if the Interupt is masked or unmasked in MPU_PROT_INTR_ERRAGG_MASK
  [4] MPU_PROT_ERRAGG_R5SS1_CPU1_STATUS_RAW_MPU_CR5A0_AXIS_PROT_ERR3 — Raw Status of Error from MPU_PROT_INTR. Set irrespective if the Interupt is masked or unmasked in MPU_PROT_INTR_ERRAGG_MASK
  [3] MPU_PROT_ERRAGG_R5SS1_CPU1_STATUS_RAW_MPU_L2_BANK_D_PROT_ERR3 — Raw Status of Error from MPU_PROT_INTR. Set irrespective if the Interupt is masked or unmasked in MPU_PROT_INTR_ERRAGG_MASK
  [2] MPU_PROT_ERRAGG_R5SS1_CPU1_STATUS_RAW_MPU_L2_BANK_C_PROT_ERR3 — Raw Status of Error from MPU_PROT_INTR. Set irrespective if the Interupt is masked or unmasked in MPU_PROT_INTR_ERRAGG_MASK
  [1] MPU_PROT_ERRAGG_R5SS1_CPU1_STATUS_RAW_MPU_L2_BANK_B_PROT_ERR3 — Raw Status of Error from MPU_PROT_INTR. Set irrespective if the Interupt is masked or unmasked in MPU_PROT_INTR_ERRAGG_MASK
  [0] MPU_PROT_ERRAGG_R5SS1_CPU1_STATUS_RAW_MPU_L2_BANK_A_PROT_ERR3 — Raw Status of Error from MPU_PROT_INTR. Set irrespective if the Interupt is masked or unmasked in MPU_PROT_INTR_ERRAGG_MASK
0x14000 MSS_CTRL_PRU_ICSS_PRU0_MBOX_WRITE_DONE
  [4n] PRU_ICSS_PRU0_MBOX_WRITE_DONE_PROC_{n} (n=0..7) — Write pulse bit field:This register should be written once finishing Writing into the mailbox memory of processor {n}
0x14004 MSS_CTRL_PRU_ICSS_PRU0_MBOX_READ_REQ
  [4n] PRU_ICSS_PRU0_MBOX_READ_REQ_PROC_{n} (n=0..7) — This is request from processor {n} to corresponding ICSSM_PRU. Requesting it to read from mailbox.
0x14008 MSS_CTRL_PRU_ICSS_PRU0_MBOX_READ_DONE_ACK
  [7:0] PRU_ICSS_PRU0_MBOX_READ_DONE_ACK_PROC — Write pulse bit field:For bits 0 to7:Wrting1'b1 : Generates pulse interrupt to corresponding proc from ICSSM_PRU0.For bits 8 to15:Wrting1'b1 : Generates pulse interrupt to corresponding proc from ICSSM_PRU1.
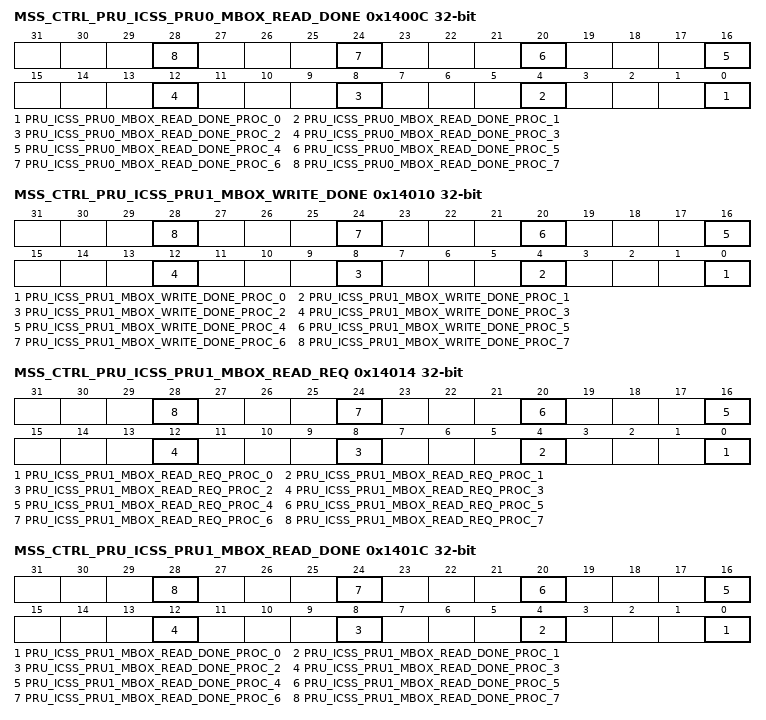
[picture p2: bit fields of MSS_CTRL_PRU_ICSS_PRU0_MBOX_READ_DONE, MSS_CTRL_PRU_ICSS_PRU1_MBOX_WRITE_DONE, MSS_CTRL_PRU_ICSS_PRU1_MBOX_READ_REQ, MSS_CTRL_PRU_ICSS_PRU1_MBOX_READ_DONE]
0x1400C MSS_CTRL_PRU_ICSS_PRU0_MBOX_READ_DONE
  [4n] PRU_ICSS_PRU0_MBOX_READ_DONE_PROC_{n} (n=0..7) — This register should be written once finishing Reading from corresponding proc{n}'s mailbox written by ICSSM_PRU
0x14010 MSS_CTRL_PRU_ICSS_PRU1_MBOX_WRITE_DONE
  [4n] PRU_ICSS_PRU1_MBOX_WRITE_DONE_PROC_{n} (n=0..7) — Write pulse bit field:This register should be written once finishing Writing into the mailbox memory of processor {n}
0x14014 MSS_CTRL_PRU_ICSS_PRU1_MBOX_READ_REQ
  [4n] PRU_ICSS_PRU1_MBOX_READ_REQ_PROC_{n} (n=0..7) — This is request from processor {n} to corresponding ICSSM_PRU. Requesting it to read from mailbox.
0x14018 MSS_CTRL_PRU_ICSS_PRU1_MBOX_READ_DONE_ACK
  [7:0] PRU_ICSS_PRU1_MBOX_READ_DONE_ACK_PROC — Write pulse bit field:For bits 0 to7:Wrting1'b1 : Generates pulse interrupt to corresponding proc from ICSSM_PRU0.For bits 8 to15:Wrting1'b1 : Generates pulse interrupt to corresponding proc from ICSSM_PRU1.
0x1401C MSS_CTRL_PRU_ICSS_PRU1_MBOX_READ_DONE
  [4n] PRU_ICSS_PRU1_MBOX_READ_DONE_PROC_{n} (n=0..7) — This register should be written once finishing Reading from corresponding proc{n}'s mailbox written by ICSSM_PRU
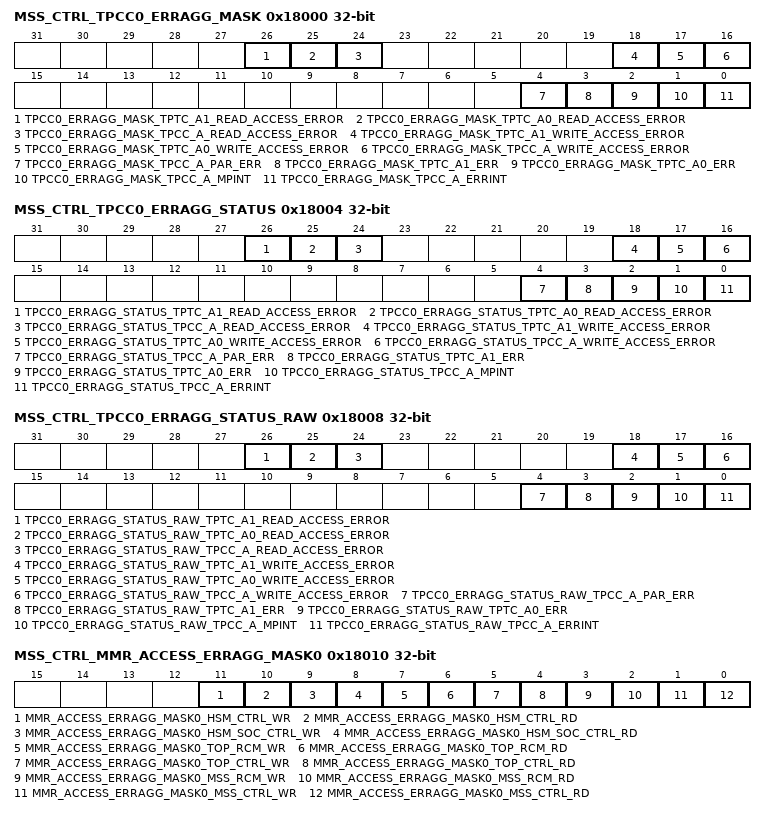
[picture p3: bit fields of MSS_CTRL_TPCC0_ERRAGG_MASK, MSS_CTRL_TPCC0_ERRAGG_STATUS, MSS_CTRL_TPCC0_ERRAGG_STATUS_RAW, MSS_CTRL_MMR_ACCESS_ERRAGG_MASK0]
0x18000 MSS_CTRL_TPCC0_ERRAGG_MASK
  [26] TPCC0_ERRAGG_MASK_TPTC_A1_READ_ACCESS_ERROR — Mask Error from MSS_TPTC_A1 to aggregated Error MSS_TPCC_A_ERRAGG1'b1 : Error is Masked1'b0 : Error is Unmasked
  [25] TPCC0_ERRAGG_MASK_TPTC_A0_READ_ACCESS_ERROR — Mask Error from MSS_TPTC_A0 to aggregated Error MSS_TPCC_A_ERRAGG1'b1 : Error is Masked1'b0 : Error is Unmasked
  [24] TPCC0_ERRAGG_MASK_TPCC_A_READ_ACCESS_ERROR — Mask Error from MSS_TPCC_A to aggregated Error MSS_TPCC_A_ERRAGG1'b1 : Error is Masked1'b0 : Error is Unmasked
  [18] TPCC0_ERRAGG_MASK_TPTC_A1_WRITE_ACCESS_ERROR — Mask Error from MSS_TPTC_A1 to aggregated Error MSS_TPCC_A_ERRAGG1'b1 : Error is Masked1'b0 : Error is Unmasked
  [17] TPCC0_ERRAGG_MASK_TPTC_A0_WRITE_ACCESS_ERROR — Mask Error from MSS_TPTC_A0 to aggregated Error MSS_TPCC_A_ERRAGG1'b1 : Error is Masked1'b0 : Error is Unmasked
  [16] TPCC0_ERRAGG_MASK_TPCC_A_WRITE_ACCESS_ERROR — Mask Error from MSS_TPCC_A to aggregated Error MSS_TPCC_A_ERRAGG1'b1 : Error is Masked1'b0 : Error is Unmasked
  [4] TPCC0_ERRAGG_MASK_TPCC_A_PAR_ERR — Mask Error from MSS_TPCC_A to aggregated Error MSS_TPCC_A_ERRAGG1'b1 : Error is Masked1'b0 : Error is Unmasked
  [3] TPCC0_ERRAGG_MASK_TPTC_A1_ERR — Mask Error from MSS_TPTC_A1 to aggregated Error MSS_TPCC_A_ERRAGG1'b1 : Error is Masked1'b0 : Error is Unmasked
  [2] TPCC0_ERRAGG_MASK_TPTC_A0_ERR — Mask Error from MSS_TPTC_A0 to aggregated Error MSS_TPCC_A_ERRAGG1'b1 : Error is Masked1'b0 : Error is Unmasked
  [1] TPCC0_ERRAGG_MASK_TPCC_A_MPINT — Mask Error from MSS_TPCC_A to aggregated Error MSS_TPCC_A_ERRAGG1'b1 : Error is Masked1'b0 : Error is Unmasked
  [0] TPCC0_ERRAGG_MASK_TPCC_A_ERRINT — Mask Error from MSS_TPCC_A to aggregated Error MSS_TPCC_A_ERRAGG1'b1 : Error is Masked1'b0 : Error is Unmasked
0x18004 MSS_CTRL_TPCC0_ERRAGG_STATUS
  [26] TPCC0_ERRAGG_STATUS_TPTC_A1_READ_ACCESS_ERROR — Status of Error from MSS_TPTC_A1. Set only if Interupt is unmasked in TPCC0_ERRAGG_MASKWrie 0x1 to clear this Error.
  [25] TPCC0_ERRAGG_STATUS_TPTC_A0_READ_ACCESS_ERROR — Status of Error from MSS_TPTC_A0. Set only if Interupt is unmasked in TPCC0_ERRAGG_MASKWrie 0x1 to clear this Error.
  [24] TPCC0_ERRAGG_STATUS_TPCC_A_READ_ACCESS_ERROR — Status of Error from MSS_TPCC_A. Set only if Interupt is unmasked in TPCC0_ERRAGG_MASKWrie 0x1 to clear this Error.
  [18] TPCC0_ERRAGG_STATUS_TPTC_A1_WRITE_ACCESS_ERROR — Status of Error from MSS_TPTC_A1. Set only if Interupt is unmasked in TPCC0_ERRAGG_MASKWrie 0x1 to clear this Error.
  [17] TPCC0_ERRAGG_STATUS_TPTC_A0_WRITE_ACCESS_ERROR — Status of Error from MSS_TPTC_A0. Set only if Interupt is unmasked in TPCC0_ERRAGG_MASKWrie 0x1 to clear this Error.
  [16] TPCC0_ERRAGG_STATUS_TPCC_A_WRITE_ACCESS_ERROR — Status of Error from MSS_TPCC_A. Set only if Interupt is unmasked in TPCC0_ERRAGG_MASKWrie 0x1 to clear this Error.
  [4] TPCC0_ERRAGG_STATUS_TPCC_A_PAR_ERR — Status of Error from MSS_TPCC_A. Set only if Interupt is unmasked in TPCC0_ERRAGG_MASKWrie 0x1 to clear this Error.
  [3] TPCC0_ERRAGG_STATUS_TPTC_A1_ERR — Status of Error from MSS_TPTC_A1. Set only if Interupt is unmasked in TPCC0_ERRAGG_MASKWrie 0x1 to clear this Error.
  [2] TPCC0_ERRAGG_STATUS_TPTC_A0_ERR — Status of Error from MSS_TPTC_A0. Set only if Interupt is unmasked in TPCC0_ERRAGG_MASKWrie 0x1 to clear this Error.
  [1] TPCC0_ERRAGG_STATUS_TPCC_A_MPINT — Status of Error from MSS_TPCC_A. Set only if Interupt is unmasked in TPCC0_ERRAGG_MASKWrie 0x1 to clear this Error.
  [0] TPCC0_ERRAGG_STATUS_TPCC_A_ERRINT — Status of Error from MSS_TPCC_A. Set only if Interupt is unmasked in TPCC0_ERRAGG_MASKWrie 0x1 to clear this Error.
0x18008 MSS_CTRL_TPCC0_ERRAGG_STATUS_RAW
  [26] TPCC0_ERRAGG_STATUS_RAW_TPTC_A1_READ_ACCESS_ERROR — Raw Status of Error from MSS_TPTC_A1. Set irrespective if the Interupt is masked or unmasked in TPCC0_ERRAGG_MASK
  [25] TPCC0_ERRAGG_STATUS_RAW_TPTC_A0_READ_ACCESS_ERROR — Raw Status of Error from MSS_TPTC_A0. Set irrespective if the Interupt is masked or unmasked in TPCC0_ERRAGG_MASK
  [24] TPCC0_ERRAGG_STATUS_RAW_TPCC_A_READ_ACCESS_ERROR — Raw Status of Error from MSS_TPCC_A. Set irrespective if the Interupt is masked or unmasked in TPCC0_ERRAGG_MASK
  [18] TPCC0_ERRAGG_STATUS_RAW_TPTC_A1_WRITE_ACCESS_ERROR — Raw Status of Error from MSS_TPTC_A1. Set irrespective if the Interupt is masked or unmasked in TPCC0_ERRAGG_MASK
  [17] TPCC0_ERRAGG_STATUS_RAW_TPTC_A0_WRITE_ACCESS_ERROR — Raw Status of Error from MSS_TPTC_A0. Set irrespective if the Interupt is masked or unmasked in TPCC0_ERRAGG_MASK
  [16] TPCC0_ERRAGG_STATUS_RAW_TPCC_A_WRITE_ACCESS_ERROR — Raw Status of Error from MSS_TPCC_A. Set irrespective if the Interupt is masked or unmasked in TPCC0_ERRAGG_MASK
  [4] TPCC0_ERRAGG_STATUS_RAW_TPCC_A_PAR_ERR — Raw Status of Error from MSS_TPCC_A. Set irrespective if the Interupt is masked or unmasked in TPCC0_ERRAGG_MASK
  [3] TPCC0_ERRAGG_STATUS_RAW_TPTC_A1_ERR — Raw Status of Error from MSS_TPTC_A1. Set irrespective if the Interupt is masked or unmasked in TPCC0_ERRAGG_MASK
  [2] TPCC0_ERRAGG_STATUS_RAW_TPTC_A0_ERR — Raw Status of Error from MSS_TPTC_A0. Set irrespective if the Interupt is masked or unmasked in TPCC0_ERRAGG_MASK
  [1] TPCC0_ERRAGG_STATUS_RAW_TPCC_A_MPINT — Raw Status of Error from MSS_TPCC_A. Set irrespective if the Interupt is masked or unmasked in TPCC0_ERRAGG_MASK
  [0] TPCC0_ERRAGG_STATUS_RAW_TPCC_A_ERRINT — Raw Status of Error from MSS_TPCC_A. Set irrespective if the Interupt is masked or unmasked in TPCC0_ERRAGG_MASK
0x18010 MSS_CTRL_MMR_ACCESS_ERRAGG_MASK0
  [11] MMR_ACCESS_ERRAGG_MASK0_HSM_CTRL_WR — Mask Interrupt from HSM_CTRL to aggregated Interrupt MSS_PERIPH_ACCESS_ERRAGG1'b1 : Interrupt is Masked1'b0 : Interrupt is Unmasked
  [10] MMR_ACCESS_ERRAGG_MASK0_HSM_CTRL_RD — Mask Interrupt from HSM_CTRL to aggregated Interrupt MSS_PERIPH_ACCESS_ERRAGG1'b1 : Interrupt is Masked1'b0 : Interrupt is Unmasked
  [9] MMR_ACCESS_ERRAGG_MASK0_HSM_SOC_CTRL_WR — Mask Interrupt from HSM_SOC_CTRL to aggregated Interrupt MSS_PERIPH_ACCESS_ERRAGG1'b1 : Interrupt is Masked1'b0 : Interrupt is Unmasked
  [8] MMR_ACCESS_ERRAGG_MASK0_HSM_SOC_CTRL_RD — Mask Interrupt from HSM_SOC_CTRL to aggregated Interrupt MSS_PERIPH_ACCESS_ERRAGG1'b1 : Interrupt is Masked1'b0 : Interrupt is Unmasked
  [7] MMR_ACCESS_ERRAGG_MASK0_TOP_RCM_WR — Mask Interrupt from TOP_RCM to aggregated Interrupt MSS_PERIPH_ACCESS_ERRAGG1'b1 : Interrupt is Masked1'b0 : Interrupt is Unmasked
  [6] MMR_ACCESS_ERRAGG_MASK0_TOP_RCM_RD — Mask Interrupt from TOP_RCM to aggregated Interrupt MSS_PERIPH_ACCESS_ERRAGG1'b1 : Interrupt is Masked1'b0 : Interrupt is Unmasked
  [5] MMR_ACCESS_ERRAGG_MASK0_TOP_CTRL_WR — Mask Interrupt from TOP_CTRL to aggregated Interrupt MSS_PERIPH_ACCESS_ERRAGG1'b1 : Interrupt is Masked1'b0 : Interrupt is Unmasked
  [4] MMR_ACCESS_ERRAGG_MASK0_TOP_CTRL_RD — Mask Interrupt from TOP_CTRL to aggregated Interrupt MSS_PERIPH_ACCESS_ERRAGG1'b1 : Interrupt is Masked1'b0 : Interrupt is Unmasked
  [3] MMR_ACCESS_ERRAGG_MASK0_MSS_RCM_WR — Mask Interrupt from MSS_RCM to aggregated Interrupt MSS_PERIPH_ACCESS_ERRAGG1'b1 : Interrupt is Masked1'b0 : Interrupt is Unmasked
  [2] MMR_ACCESS_ERRAGG_MASK0_MSS_RCM_RD — Mask Interrupt from MSS_RCM to aggregated Interrupt MSS_PERIPH_ACCESS_ERRAGG1'b1 : Interrupt is Masked1'b0 : Interrupt is Unmasked
  [1] MMR_ACCESS_ERRAGG_MASK0_MSS_CTRL_WR — Mask Interrupt from MSS_CTRL to aggregated Interrupt MSS_PERIPH_ACCESS_ERRAGG1'b1 : Interrupt is Masked1'b0 : Interrupt is Unmasked
  [0] MMR_ACCESS_ERRAGG_MASK0_MSS_CTRL_RD — Mask Interrupt from MSS_CTRL to aggregated Interrupt MSS_PERIPH_ACCESS_ERRAGG1'b1 : Interrupt is Masked1'b0 : Interrupt is Unmasked
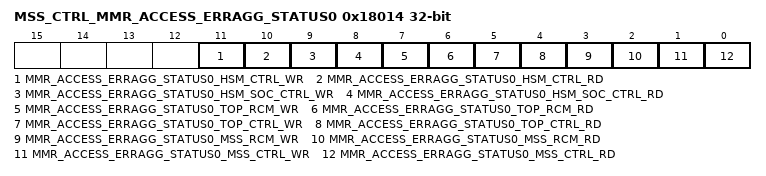
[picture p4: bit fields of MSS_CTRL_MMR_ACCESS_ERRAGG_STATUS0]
0x18014 MSS_CTRL_MMR_ACCESS_ERRAGG_STATUS0
  [11] MMR_ACCESS_ERRAGG_STATUS0_HSM_CTRL_WR — Status of Interrupt from HSM_CTRLSet only if Interupt is unmasked in MMR_ACCESS_ERRAGG_MASK0Wrie 0x1 to clear this interrupt.
  [10] MMR_ACCESS_ERRAGG_STATUS0_HSM_CTRL_RD — Status of Interrupt from HSM_CTRLSet only if Interupt is unmasked in MMR_ACCESS_ERRAGG_MASK0Wrie 0x1 to clear this interrupt.
  [9] MMR_ACCESS_ERRAGG_STATUS0_HSM_SOC_CTRL_WR — Status of Interrupt from HSM_SOC_CTRLSet only if Interupt is unmasked in MMR_ACCESS_ERRAGG_MASK0Wrie 0x1 to clear this interrupt.
  [8] MMR_ACCESS_ERRAGG_STATUS0_HSM_SOC_CTRL_RD — Status of Interrupt from HSM_SOC_CTRLSet only if Interupt is unmasked in MMR_ACCESS_ERRAGG_MASK0Wrie 0x1 to clear this interrupt.
  [7] MMR_ACCESS_ERRAGG_STATUS0_TOP_RCM_WR — Status of Interrupt from TOP_RCMSet only if Interupt is unmasked in MMR_ACCESS_ERRAGG_MASK0Wrie 0x1 to clear this interrupt.
  [6] MMR_ACCESS_ERRAGG_STATUS0_TOP_RCM_RD — Status of Interrupt from TOP_RCMSet only if Interupt is unmasked in MMR_ACCESS_ERRAGG_MASK0Wrie 0x1 to clear this interrupt.
  [5] MMR_ACCESS_ERRAGG_STATUS0_TOP_CTRL_WR — Status of Interrupt from TOP_CTRLSet only if Interupt is unmasked in MMR_ACCESS_ERRAGG_MASK0Wrie 0x1 to clear this interrupt.
  [4] MMR_ACCESS_ERRAGG_STATUS0_TOP_CTRL_RD — Status of Interrupt from TOP_CTRLSet only if Interupt is unmasked in MMR_ACCESS_ERRAGG_MASK0Wrie 0x1 to clear this interrupt.
  [3] MMR_ACCESS_ERRAGG_STATUS0_MSS_RCM_WR — Status of Interrupt from MSS_RCMSet only if Interupt is unmasked in MMR_ACCESS_ERRAGG_MASK0Wrie 0x1 to clear this interrupt.
  [2] MMR_ACCESS_ERRAGG_STATUS0_MSS_RCM_RD — Status of Interrupt from MSS_RCMSet only if Interupt is unmasked in MMR_ACCESS_ERRAGG_MASK0Wrie 0x1 to clear this interrupt.
  [1] MMR_ACCESS_ERRAGG_STATUS0_MSS_CTRL_WR — Status of Interrupt from MSS_CTRLSet only if Interupt is unmasked in MMR_ACCESS_ERRAGG_MASK0Wrie 0x1 to clear this interrupt.
  [0] MMR_ACCESS_ERRAGG_STATUS0_MSS_CTRL_RD — Status of Interrupt from MSS_CTRLSet only if Interupt is unmasked in MMR_ACCESS_ERRAGG_MASK0Wrie 0x1 to clear this interrupt.
